# MB9BF16xN register map
Vendor: Cypress; File version: 2.1
CPU: CM4 r0p1, little endian, MPU, FPU, 4 interrupt priority bits
Registers are 32-bit, read-write, reset 0x0 unless marked. A register's access mark holds for its fields unless they carry their own. Offsets are from the block's base; [hi:lo] are bit positions; {n}, {i} and the like mark numbered series; 'fields as' and 'values as' point back to an identical list.

## SDIF — SD Card Interface
Base 0x4006E000
0x00 SSA2 — SDMA System Address / Argument 2 Register [BHW]
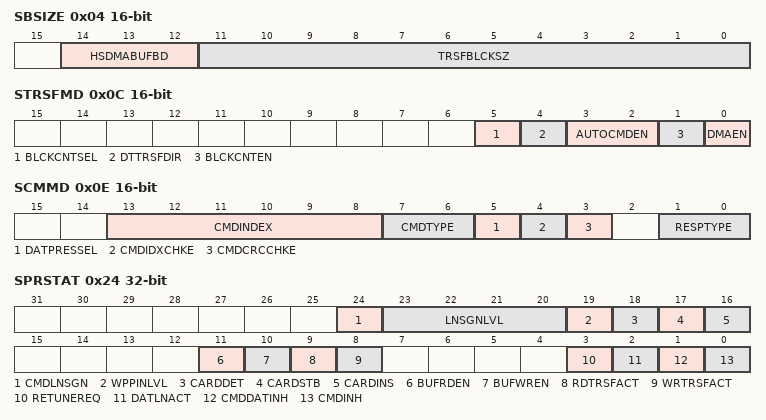
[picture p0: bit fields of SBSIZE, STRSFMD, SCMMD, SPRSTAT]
0x04 SBSIZE 16-bit — Block Size Register [BHW]
  [14:12] HSDMABUFBD — Host SDMA Buffer Boundary
  [11:0] TRSFBLCKSZ — Transfer Block Size
0x06 SBLCNT 16-bit — Block Count Register [BHW]
0x08 SSA1 — Argument 1 Register [BHW]
0x0C STRSFMD 16-bit (reset mask 0x37) — Transfer Mode Register [BHW]
  [5] BLCKCNTSEL — Multi / Single Block select
  [4] DTTRSFDIR — Data Transfer Direction Select
  [3:2] AUTOCMDEN — Auto Command Enable
  [1] BLCKCNTEN — Block Count Enable
  [0] DMAEN — DMA Enable
0x0E SCMMD 16-bit — Command Register [BHW]
  [13:8] CMDINDEX — Command Index
  [7:6] CMDTYPE — Command Type
  [5] DATPRESSEL — Data Present Select
  [4] CMDIDXCHKE — Command Index Check Enable
  [3] CMDCRCCHKE — Command CRC Check Enable
  [1:0] RESPTYPE — Response Type Select
{0x10+2i} SRESP{i} 16-bit ro (i=0..7) — Response Register {i} [BHW]
0x20 SBUFDP — Buffer Data Port Register [BHW]
0x24 SPRSTAT ro (reset mask 0x10F0F07) — Present State Register [BHW]
  [24] CMDLNSGN — CMD Line Signal Level
  [23:20] LNSGNLVL — DAT Line Signal Level
  [19] WPPINLVL — Write Protect Switch Pin Level
  [18] CARDDET — Card Detect Pin Level
  [17] CARDSTB — Card State Stable
  [16] CARDINS — Card Inserted
  [11] BUFRDEN — Buffer Read Enable
  [10] BUFWREN — Buffer Write Enable
  [9] RDTRSFACT — Read Transfer Active
  [8] WRTRSFACT — Write Transfer Active
  [3] RETUNEREQ — Re-Tuning Request
  [2] DATLNACT — DAT Line Active
  [1] CMDDATINH — Command Inhibit (DAT)
  [0] CMDINH — Command Inhibit (CMD)
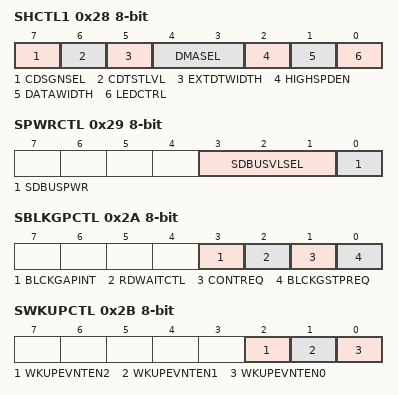
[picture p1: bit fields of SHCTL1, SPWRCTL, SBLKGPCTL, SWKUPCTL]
0x28 SHCTL1 8-bit — Host Control 1 Register [BHW]
  [7] CDSGNSEL — Card Detect Signal Selection
  [6] CDTSTLVL — Card Detect Test Level
  [5] EXTDTWIDTH — Extended Data Transfer Width
  [4:3] DMASEL — DMA Select
  [2] HIGHSPDEN — High Speed Enable
  [1] DATAWIDTH — Data Transfer Width
  [0] LEDCTRL — LED Control
0x29 SPWRCTL 8-bit — Power Control Register [BHW]
  [3:1] SDBUSVLSEL — SD Bus Voltage Select
  [0] SDBUSPWR — SD Bus Power
0x2A SBLKGPCTL 8-bit — Block Gap Control Register [BHW]
  [3] BLCKGAPINT — Interrupt At Block Gap
  [2] RDWAITCTL — Read Wait Control
  [1] CONTREQ — Continue Request
  [0] BLCKGSTPREQ — Stop At Block Gap Request
0x2B SWKUPCTL 8-bit — Wakeup Control Register [BHW]
  [2] WKUPEVNTEN2 — Wakeup Event Enable On SD Card Removal
  [1] WKUPEVNTEN1 — Wakeup Event Enable On SD Card Insertion
  [0] WKUPEVNTEN0 — Wakeup Event Enable On SD Card Interrupt
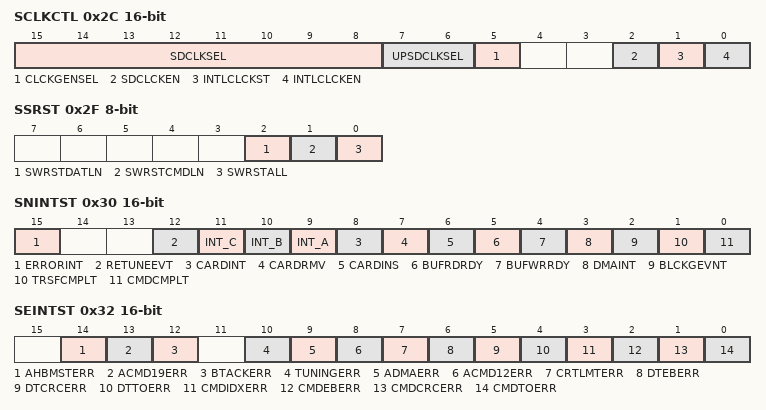
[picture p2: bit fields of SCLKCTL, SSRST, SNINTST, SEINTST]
0x2C SCLKCTL 16-bit — Clock Control Register [BHW]
  [15:8] SDCLKSEL — SDCLK Frequency Select
  [7:6] UPSDCLKSEL — Upper Bits of SDCLK Frequency Select
  [5] CLCKGENSEL — Clock Generator Select
  [2] SDCLCKEN — SD Clock Enable
  [1] INTLCLCKST ro — Internal Clock Stable
  [0] INTLCLCKEN — Internal Clock Enable
0x2E STOCTL 8-bit — Timeout Control Register [BHW]
  [3:0] DTTMOUTVAL — Data Timeout Counter Value
0x2F SSRST 8-bit — Software Reset Register [BHW]
  [2] SWRSTDATLN — Software Reset for DAT Line
  [1] SWRSTCMDLN — Software Reset for CMD Line
  [0] SWRSTALL — Software Reset for All
0x30 SNINTST 16-bit ro — Normal Interrupt Status Register [BHW]
  [15] ERRORINT — Error Interrupt
  [12] RETUNEEVT — Re-Tuning Event
  [11] INT_C — INT_C Interrupt
  [10] INT_B — INT_B Interrupt
  [9] INT_A — INT_A Interrupt
  [8] CARDINT — Card Interrupt
  [7] CARDRMV — Card Removal
  [6] CARDINS — Card Insertion
  [5] BUFRDRDY — Buffer Read Ready
  [4] BUFWRRDY — Buffer Write Ready
  [3] DMAINT — DMA Interrupt
  [2] BLCKGEVNT — Block Gap Event
  [1] TRSFCMPLT — Transfer Complete
  [0] CMDCMPLT — Command Complete
0x32 SEINTST 16-bit ro (reset mask 0x73FF) — Error Interrupt Status Register [BHW]
  [14] AHBMSTERR — AHB Master Error
  [13] ACMD19ERR — Auto CMD19 Error
  [12] BTACKERR — Boot Acknowledge Error
  [10] TUNINGERR — Tuning Error
  [9] ADMAERR — ADMA Error
  [8] ACMD12ERR — Auto CMD12 Error
  [7] CRTLMTERR — Current Limit Error
  [6] DTEBERR — Data End Bit Error
  [5] DTCRCERR — Data CRC Error
  [4] DTTOERR — Data Timeout Error
  [3] CMDIDXERR — Command Index Error
  [2] CMDEBERR — Command End Bit Error
  [1] CMDCRCERR — Command CRC Error
  [0] CMDTOERR — Command Timeout Error
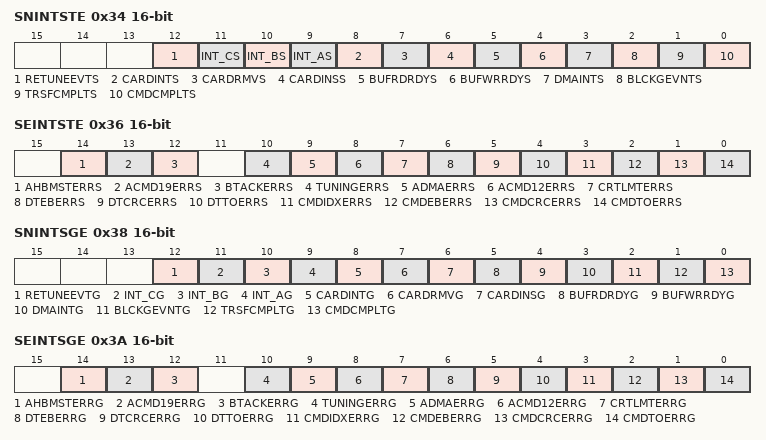
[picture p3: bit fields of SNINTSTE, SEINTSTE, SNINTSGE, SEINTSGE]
0x34 SNINTSTE 16-bit — Normal Interrupt Status Enable Register [BHW]
  [12] RETUNEEVTS — Re-Tuning Event Status Enable
  [11] INT_CS — INT_C Status Enable
  [10] INT_BS — INT_B Status Enable
  [9] INT_AS — INT_A Status Enable
  [8] CARDINTS — Card Interrupt Status Enable
  [7] CARDRMVS — Card Removal Status Enable
  [6] CARDINSS — Card Insertion Status Enable
  [5] BUFRDRDYS — Buffer Read Ready Status Enable
  [4] BUFWRRDYS — Buffer Write Ready Status Enable
  [3] DMAINTS — DMA Interrupt Status Enable
  [2] BLCKGEVNTS — Block Gap Event Status Enable
  [1] TRSFCMPLTS — Transfer Complete Status Enable
  [0] CMDCMPLTS — Command Complete Status Enable
0x36 SEINTSTE 16-bit — Error Interrupt Status Enable Register [BHW]
  [14] AHBMSTERRS — AHB Master Error Status Enable
  [13] ACMD19ERRS — Auto CMD19 Error Status Enable
  [12] BTACKERRS — Boot Acknowledge Error Status Enable
  [10] TUNINGERRS — Tuning Error Status Enable
  [9] ADMAERRS — ADMA Error Status Enable
  [8] ACMD12ERRS — Auto CMD Error Status Enable
  [7] CRTLMTERRS — Current limit Error Status Enable
  [6] DTEBERRS — Data End Bit Error Status Enable
  [5] DTCRCERRS — Data CRC Error Status Enable
  [4] DTTOERRS — Data Timeout Error Status Enable
  [3] CMDIDXERRS — Command Index Error Status Enable
  [2] CMDEBERRS — Command End Bit Error Status Enable
  [1] CMDCRCERRS — Command CRC Error Status Enable
  [0] CMDTOERRS — Command Timeout Error Status Enable
0x38 SNINTSGE 16-bit — Normal Interrupt Signal Enable Register [BHW]
  [12] RETUNEEVTG — Re-Tuning Event Signal Enable
  [11] INT_CG — INT_C Signal Enable
  [10] INT_BG — INT_B Signal Enable
  [9] INT_AG — INT_A Signal Enable
  [8] CARDINTG — Card Interrupt Signal Enable
  [7] CARDRMVG — Card Removal Signal Enable
  [6] CARDINSG — Card Insertion Signal Enable
  [5] BUFRDRDYG — Buffer Read Ready Signal Enable
  [4] BUFWRRDYG — Buffer Write Ready Signal Enable
  [3] DMAINTG — DMA Interrupt Signal Enable
  [2] BLCKGEVNTG — Block Gap Event Signal Enable
  [1] TRSFCMPLTG — Transfer Complete Signal Enable
  [0] CMDCMPLTG — Command Complete Signal Enable
0x3A SEINTSGE 16-bit — Error Interrupt Signal Enable Register [BHW]
  [14] AHBMSTERRG — AHB Master Error Signal Enable
  [13] ACMD19ERRG — Auto CMD19 Error Signal Enable
  [12] BTACKERRG — Boot Acknowledge Error Signal Enable
  [10] TUNINGERRG — Tuning Error Signal Enable
  [9] ADMAERRG — ADMA Error Signal Enable
  [8] ACMD12ERRG — Auto CMD Error Signal Enable
  [7] CRTLMTERRG — Current limit Error Signal Enable
  [6] DTEBERRG — Data End Bit Error Signal Enable
  [5] DTCRCERRG — Data CRC Error Signal Enable
  [4] DTTOERRG — Data Timeout Error Signal Enable
  [3] CMDIDXERRG — Command Index Error Signal Enable
  [2] CMDEBERRG — Command End Bit Error Signal Enable
  [1] CMDCRCERRG — Command CRC Error Signal Enable
  [0] CMDTOERRG — Command Timeout Error Signal Enable
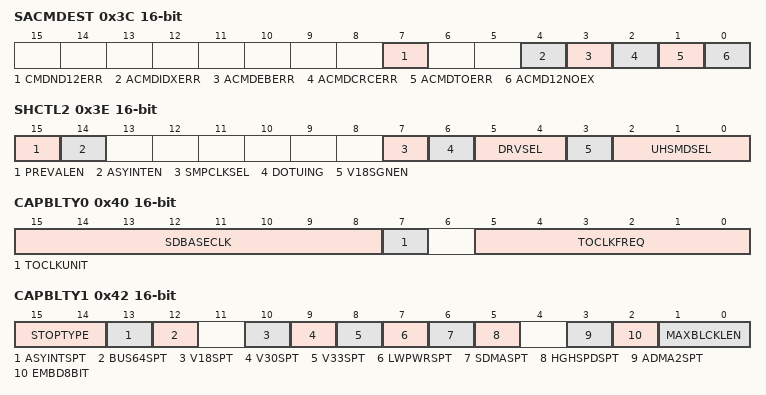
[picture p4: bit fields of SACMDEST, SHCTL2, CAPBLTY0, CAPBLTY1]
0x3C SACMDEST 16-bit ro — Auto CMD Error Status Register [BHW]
  [7] CMDND12ERR — Command Not Issued by Auto CMD12 Error
  [4] ACMDIDXERR — Auto CMD Index Error
  [3] ACMDEBERR — Auto CMD End Bit Error
  [2] ACMDCRCERR — Auto CMD CRC Error
  [1] ACMDTOERR — Auto CMD Timeout Error
  [0] ACMD12NOEX — Auto CMD12 not executed
0x3E SHCTL2 16-bit — Host Control 2 Register [BHW]
  [15] PREVALEN — Preset Value Enable
  [14] ASYINTEN — Asynchronous Interrupt Enable
  [7] SMPCLKSEL — Sampling Clock Select
  [6] DOTUING — Execute Tuning
  [5:4] DRVSEL — Driver Strength Select
  [3] V18SGNEN — 1.8V Signaling Enable
  [2:0] UHSMDSEL — UHS Mode Select
0x40 CAPBLTY0 16-bit ro (reset mask 0xFB00) — Capabilities Register 0 [BHW]
  [15:8] SDBASECLK — Base Clock Frequency For SD Clock
  [7] TOCLKUNIT — Timeout Clock Unit
  [5:0] TOCLKFREQ — Timeout Clock Frequency
0x42 CAPBLTY1 16-bit ro — Capabilities Register 1 [BHW]
  [15:14] STOPTYPE — Slot Type
  [13] ASYINTSPT — Asynchronous Interrupt Support
  [12] BUS64SPT — 64-bit System Bus Support
  [10] V18SPT — Voltage Support 1.8V
  [9] V30SPT — Voltage Support 3.0V
  [8] V33SPT — Voltage Support 3.3V
  [7] LWPWRSPT — Suspend/Resume Suppoort
  [6] SDMASPT — SDMA Support
  [5] HGHSPDSPT — High Speed Support
  [3] ADMA2SPT — ADMA2 Support
  [2] EMBD8BIT — 8-bit Support for Embedded Device
  [1:0] MAXBLCKLEN — Max Block Length
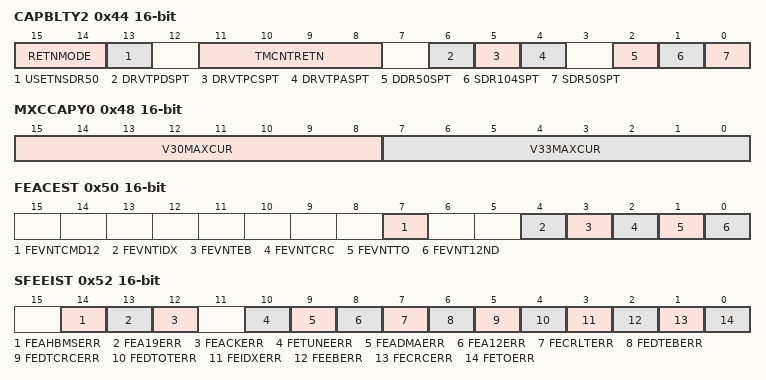
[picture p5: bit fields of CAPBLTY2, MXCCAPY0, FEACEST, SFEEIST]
0x44 CAPBLTY2 16-bit ro — Capabilities Register 2 [BHW]
  [15:14] RETNMODE — Re-Tuning Modes
  [13] USETNSDR50 — Use Tuning for SDR50
  [11:8] TMCNTRETN — Timer Count for Re-Tuning
  [6] DRVTPDSPT — Driver Type D Support
  [5] DRVTPCSPT — Driver Type C Support
  [4] DRVTPASPT — Driver Type A Support
  [2] DDR50SPT — DDR50 Support
  [1] SDR104SPT — SDR104 Support
  [0] SDR50SPT — SDR50 Support
0x46 CAPBLTY3 16-bit ro — Capabilities Register 3 [BHW]
  [7:0] CLKMULTPL — Clock Multiplier
0x48 MXCCAPY0 16-bit ro — Maximum Current Capabilities Register 0 [BHW]
  [15:8] V30MAXCUR — Maximum Current for 3.0V
  [7:0] V33MAXCUR — Maximum Current for 3.3V
0x4A MXCCAPY1 16-bit ro — Maximum Current Capabilities Register 1 [BHW]
  [7:0] V18MAXCUR — Maximum Current for 1.8V
0x4C MXCCAPY2 16-bit ro reset not defined — Maximum Current Capabilities Register 2 [BHW]
0x4E MXCCAPY3 16-bit ro reset not defined — Maximum Current Capabilities Register 3 [BHW]
0x50 FEACEST 16-bit wo — Force Event Register for Auto CMD Error Status [BHW]
  [7] FEVNTCMD12 — Force Event for Command Not Issued by Auto CMD12 Error
  [4] FEVNTIDX — Force Event for Auto CMD Index Error
  [3] FEVNTEB — Force Event for Auto CMD End Bit Error
  [2] FEVNTCRC — Force Event for Auto CMD CRC Error
  [1] FEVNTTO — Force Event for Auto CMD Timeout Error
  [0] FEVNT12ND — Force Event for Auto CMD12 not executed
0x52 SFEEIST 16-bit wo — Force Event Register for Error Interrupt Status [BHW]
  [14] FEAHBMSERR — Force Event for AHB Master Error
  [13] FEA19ERR — Force Event for Auto CMD19 Error
  [12] FEACKERR — Force Event for Boot Acknowledge Error
  [10] FETUNEERR — Force Event for Tuning Error
  [9] FEADMAERR — Force Event for ADMA Error
  [8] FEA12ERR — Force Event for Auto CMD12 Error
  [7] FECRLTERR — Force Event for Current limit Error
  [6] FEDTEBERR — Force Event for Data End Bit Error
  [5] FEDTCRCERR — Force Event for Data CRC Error
  [4] FEDTOTERR — Force Event for Data Timeout Error
  [3] FEIDXERR — Force Event for Command Index Error
  [2] FEEBERR — Force Event for Command End Bit Error
  [1] FECRCERR — Force Event for Command CRC Error
  [0] FETOERR — Force Event for Command Timeout Error
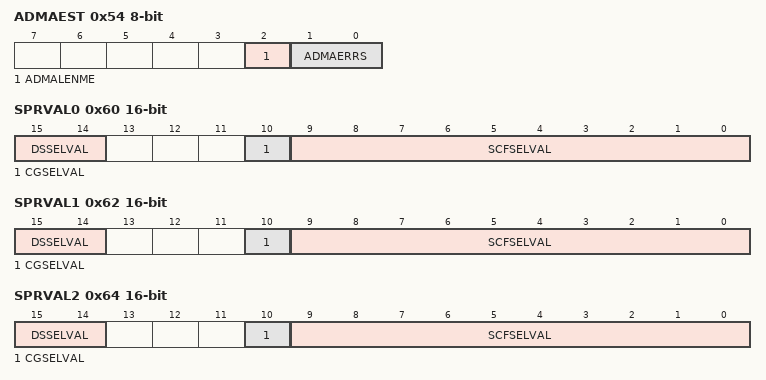
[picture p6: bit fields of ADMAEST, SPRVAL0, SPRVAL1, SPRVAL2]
0x54 ADMAEST 8-bit — ADMA Error Status Register [BHW]
  [2] ADMALENME — ADMA Length Mismatch Error
  [1:0] ADMAERRS — ADMA Error Status
{0x58+2i} SADSA{i} 16-bit (i=0..3) — ADMA System Address Register {i} [BHW]
  [15:0] ADR{1616i+1500} — AdMA System Address [{16i+15}:{16i}]
0x60 SPRVAL0 16-bit — Preset Value Register for Initialization [BHW]
  [15:14] DSSELVAL — Driver Strength Select Value
  [10] CGSELVAL — Clock Generator Select Value
  [9:0] SCFSELVAL — SDCLK Frequency Select Value
0x62 SPRVAL1 16-bit — Preset Value Register for Default Speed [BHW]
  fields as SPRVAL0
0x64 SPRVAL2 16-bit — Preset Value Register for High Speed [BHW]
  fields as SPRVAL0
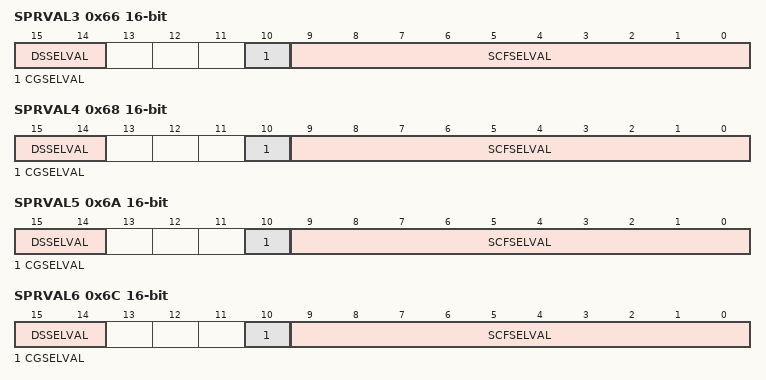
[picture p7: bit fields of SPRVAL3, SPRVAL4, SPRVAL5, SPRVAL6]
0x66 SPRVAL3 16-bit — Preset Value Register for SDR12 [BHW]
  fields as SPRVAL0
0x68 SPRVAL4 16-bit — Preset Value Register for SDR25 [BHW]
  fields as SPRVAL0
0x6A SPRVAL5 16-bit — Preset Value Register for SDR50 [BHW]
  fields as SPRVAL0
0x6C SPRVAL6 16-bit — Preset Value Register for SDR104 [BHW]
  fields as SPRVAL0
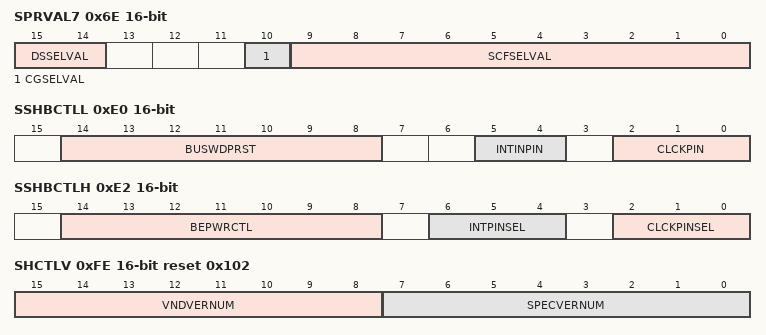
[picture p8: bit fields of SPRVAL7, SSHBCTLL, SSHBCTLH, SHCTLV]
0x6E SPRVAL7 16-bit — Preset Value Register for DDR50 [BHW]
  fields as SPRVAL0
0xE0 SSHBCTLL 16-bit — Shared Bus Control Register L [BHW]
  [14:8] BUSWDPRST — Bus Width Preset
  [5:4] INTINPIN — Number of Interrupt Input Pins
  [2:0] CLCKPIN — Number of Clock Pins
0xE2 SSHBCTLH 16-bit — Shared Bus Control Register H [BHW]
  [14:8] BEPWRCTL — Back-End Power Control
  [6:4] INTPINSEL — Interrupt Pin Select
  [2:0] CLCKPINSEL — Clock Pin Select
0xFC SSLIST 16-bit ro — Slot Interrupt Status Register [BHW]
  [7:0] SLOTINTSGN — Interrupt Signal For Each Slot
0xFE SHCTLV 16-bit ro reset 0x102 — Host Controller Version Register [BHW]
  [15:8] VNDVERNUM — Vendor Version Number
  [7:0] SPECVERNUM — Specification Version Number
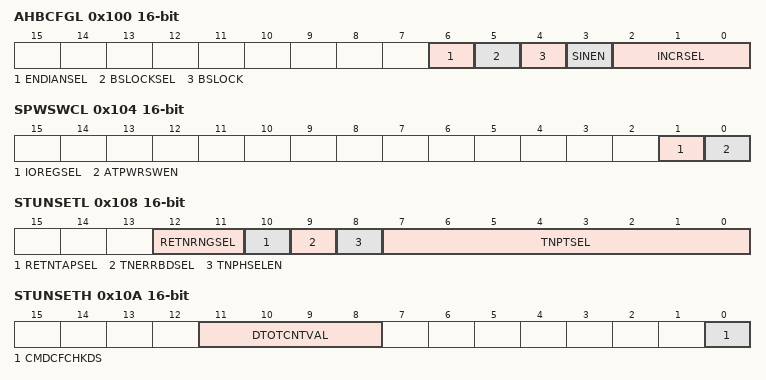
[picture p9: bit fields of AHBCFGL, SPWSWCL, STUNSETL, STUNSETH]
0x100 AHBCFGL 16-bit — AHB Config Register L [BHW]
  [6] ENDIANSEL — Big/Little Endian Select
  [5] BSLOCKSEL — Bus Lock Select
  [4] BSLOCK — Bus Lock Function
  [3] SINEN — Burst type for byte transfer Select
  [2:0] INCRSEL — AHB fixed length burst type Select
0x102 AHBCFGH 16-bit reset not defined — AHB Config Registe H [BHW]
0x104 SPWSWCL 16-bit — Power Switching Register L [BHW]
  [1] IOREGSEL — I/O Register Selecting
  [0] ATPWRSWEN — Auto Power Switching Select
0x106 SPWSWCH 16-bit reset not defined — Power Switching Register H [BHW]
0x108 STUNSETL 16-bit — Tuning Setting Register L [BHW]
  [12:11] RETNRNGSEL — Re-Tuning Range Select
  [10] RETNTAPSEL — Re-Tuning Tap Select
  [9] TNERRBDSEL — Tuning Error Border Select
  [8] TNPHSELEN — Tuning Phase Select Enable
  [7:0] TNPTSEL — Tuning Point Select
0x10A STUNSETH 16-bit — Tuning Setting Register H [BHW]
  [11:8] DTOTCNTVAL — Data Timeout Counter Value For Auto Re-Tuning
  [0] CMDCFCHKDS — CMD Conflict Check Disable
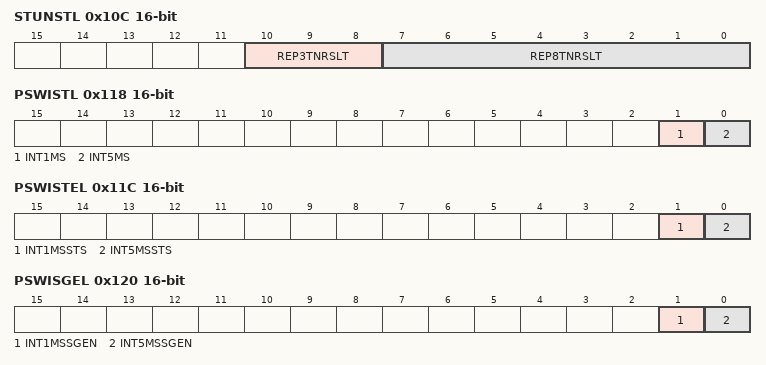
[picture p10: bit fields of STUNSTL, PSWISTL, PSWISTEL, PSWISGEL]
0x10C STUNSTL 16-bit ro — Tuning Status Register L [BHW]
  [10:8] REP3TNRSLT — 3 Phase Re-Tuning Result
  [7:0] REP8TNRSLT — 8 Phase Tuning / Re-Tuning Result
0x10E STUNSTH 16-bit ro — Tuning Status Register H [BHW]
  [7:0] PRSTTNPNT — Present Tuning point
0x118 PSWISTL 16-bit ro — Power Switching Interrupt Status Register L [BHW]
  [1] INT1MS — 1ms Wait Interrupt
  [0] INT5MS — 5ms Wait Interrupt
0x11A PSWISTH 16-bit ro reset not defined — Power Switching Interrupt Status Register H [BHW]
0x11C PSWISTEL 16-bit — Power Switching Interrupt Status Enable Register L [BHW]
  [1] INT1MSSTS — 1ms Wait Interrupt Status Enable
  [0] INT5MSSTS — 5ms Wait Interrupt Status Enable
0x11E PSWISTEH 16-bit reset not defined — Power Switching Interrupt Status Enable Register H [BHW]
0x120 PSWISGEL 16-bit — Power Switching Interrupt Signal Enable Register L [BHW]
  [1] INT1MSSGEN — 1ms Wait Interrupt Signal Enable
  [0] INT5MSSGEN — 5ms Wait Interrupt Signal Enable
0x122 PSWISGEH 16-bit reset not defined — Power Switching Interrupt Signal Enable Register H [BHW]
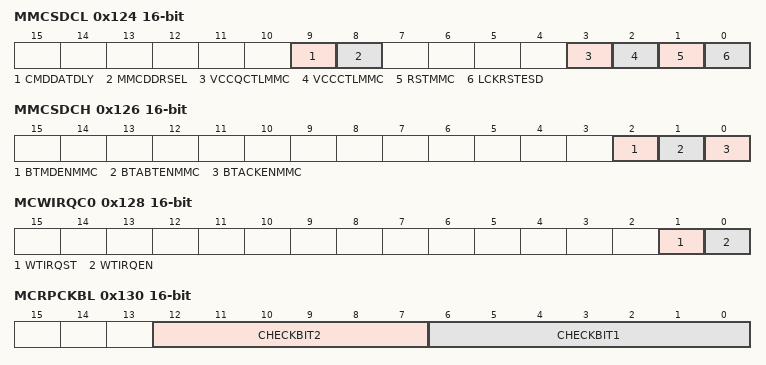
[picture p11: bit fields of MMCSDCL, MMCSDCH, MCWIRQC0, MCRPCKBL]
0x124 MMCSDCL 16-bit — MMC/eSD Control Register L [BHW]
  [9] CMDDATDLY — CMD / DAT Delay Select
  [8] MMCDDRSEL — MMC DDR Select
  [3] VCCQCTLMMC — VCCQ Control for MMC
  [2] VCCCTLMMC — VCC Control for MMC
  [1] RSTMMC — RST_n Control for MMC
  [0] LCKRSTESD — Lock-Reset Control for MMC
0x126 MMCSDCH 16-bit — MMC/eSD Control Register H [BHW]
  [2] BTMDENMMC — Boot Mode Enable for MMC
  [1] BTABTENMMC — Boot Auto Abort Enable for MMC
  [0] BTACKENMMC — Boot Ack Enable for MMC
0x128 MCWIRQC0 16-bit — MMC Wait IRQ Control Register 0 [BHW]
  [1] WTIRQST — Wait IRQ State
  [0] WTIRQEN — Wait IRQ Enable
{0x128+2i} MCWIRQC{i} 16-bit (i=1..3) — MMC Wait IRQ Control Register {i} [BHW]
  [15:0] WTIRQCNCLR — Wait IRQ Cancel Response
0x130 MCRPCKBL 16-bit ro — MMC Response Check Bit Register L [BHW]
  [12:7] CHECKBIT2, [6:0] CHECKBIT1
0x132 MCRPCKBH 16-bit ro reset not defined — MMC Response Check Bit Register H [BHW]
0x154 SCDETECS 16-bit ro — Card Detect Setting Register [BHW]
  [11:8] CDDEBTCVAL — Card Detect Debounce Timer Counter Value

## Notices in the file
Copyright (C) 2013-2016, Cypress Semiconductor Corporation or a
subsidiary of Cypress Semiconductor Corporation.  All rights reserved.
This software, including source code, documentation and related
materials ("Software"), is owned by Cypress Semiconductor Corporation or
one of its subsidiaries ("Cypress") and is protected by and subject to
worldwide patent protection (United States and foreign), United States
copyright laws and international treaty provisions. Therefore, you may use
this Software only as provided in the license agreement accompanying the
software package from which you obtained this Software ("EULA").
If no EULA applies, Cypress hereby grants you a personal, non-exclusive,
non-transferable license to copy, modify, and compile the
Software source code solely for use in connection with Cypress's
integrated circuit products.  Any reproduction, modification, translation,
compilation, or representation of this Software except as specified
above is prohibited without the express written permission of Cypress.
Disclaimer: THIS SOFTWARE IS PROVIDED AS-IS, WITH NO
WARRANTY OF ANY KIND, EXPRESS OR IMPLIED, INCLUDING,
BUT NOT LIMITED TO, NONINFRINGEMENT, IMPLIED
WARRANTIES OF MERCHANTABILITY AND FITNESS FOR A
PARTICULAR PURPOSE. Cypress reserves the right to make
changes to the Software without notice. Cypress does not assume any
liability arising out of the application or use of the Software or any
product or circuit described in the Software. Cypress does not
authorize its products for use in any products where a malfunction or
failure of the Cypress product may reasonably be expected to result in
significant property damage, injury or death ("High Risk Product"). By
including Cypress's product in a High Risk Product, the manufacturer
of such system or application assumes all risk of such use and in doing
so agrees to indemnify Cypress against all liability.
